# MIMXRT685S_cm33 register map
Vendor: nxp.com; File version: 1.0
CPU: CM33 r2p0, little endian, MPU, FPU, VTOR, 3 interrupt priority bits
Registers are 32-bit, read-write, reset 0x0 unless marked. A register's access mark holds for its fields unless they carry their own. Offsets are from the block's base; [hi:lo] are bit positions; {n}, {i} and the like mark numbered series; 'fields as' and 'values as' point back to an identical list.

## AHB_SECURE_CTRL — LPC_Next0 AHB secure controller
Base 0x40148000
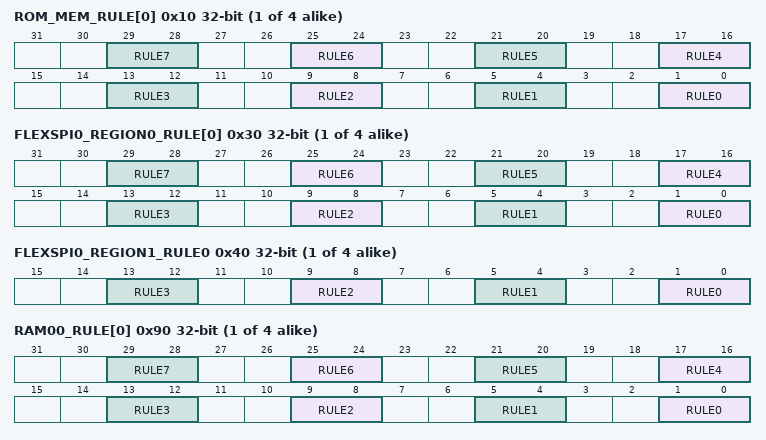
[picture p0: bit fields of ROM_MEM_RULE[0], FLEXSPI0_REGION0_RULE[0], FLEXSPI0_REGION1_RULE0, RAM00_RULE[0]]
{0x10+4i} ROM_MEM_RULE[{i}] (i=0..3) — Memory ROM Rule(n) Register
  [all] fields
    0=NONSECURE_NONPRIV_USER_ALLOWED (Non-secure and non-privilege user access allowed); 1=NONSECURE_PRIV_USER_ALLOWED (Non-secure and privilege access allowed); 2=SECURE_NONPRIV_USER_ALLOWED (Secure and non-privilege user access allowed); 3=SECURE_PRIV_USER_ALLOWED (Secure and privilege user access allowed)
  [4n+1:4n] RULE{n} (n=0..7)
{0x30+4i} FLEXSPI0_REGION0_RULE[{i}] (i=0..3) — FLEXSPI0 Region 0 Rule(n) Register
  fields as ROM_MEM_RULE[0]
{0x30+0x10*i} FLEXSPI0_REGION{i}_RULE0 (i=1..4)
  [all] fields
    values as the fields of ROM_MEM_RULE[0]
  [4n+1:4n] RULE{n} (n=0..3)
{0x90+4i} RAM00_RULE[{i}] (i=0..3) — SRAM Partition 00 Rule(n) Register
  fields as ROM_MEM_RULE[0]
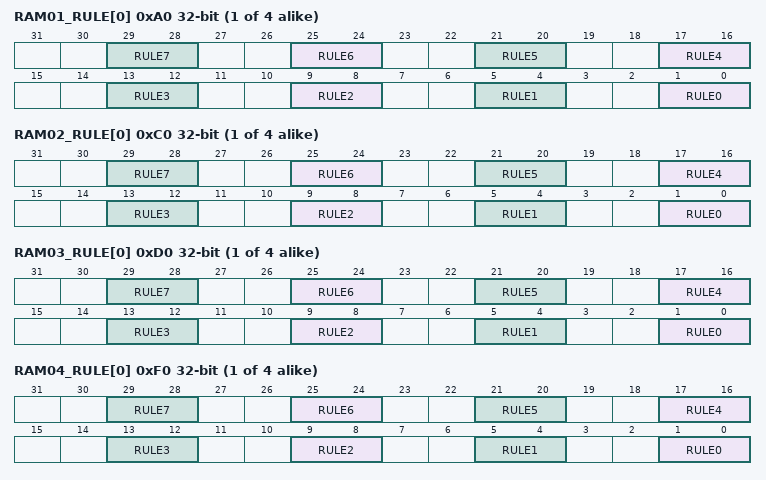
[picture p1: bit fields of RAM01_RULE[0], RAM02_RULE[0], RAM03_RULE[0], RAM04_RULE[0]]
{0xA0+4i} RAM01_RULE[{i}] (i=0..3) — SRAM Partition 01 Rule(n) Register
  fields as ROM_MEM_RULE[0]
{0xC0+4i} RAM02_RULE[{i}] (i=0..3) — SRAM Partition 02 Rule(n) Register
  fields as ROM_MEM_RULE[0]
{0xD0+4i} RAM03_RULE[{i}] (i=0..3) — SRAM Partition 03 Rule(n) Register
  fields as ROM_MEM_RULE[0]
{0xF0+4i} RAM04_RULE[{i}] (i=0..3) — SRAM Partition 04 Rule(n) Register
  fields as ROM_MEM_RULE[0]
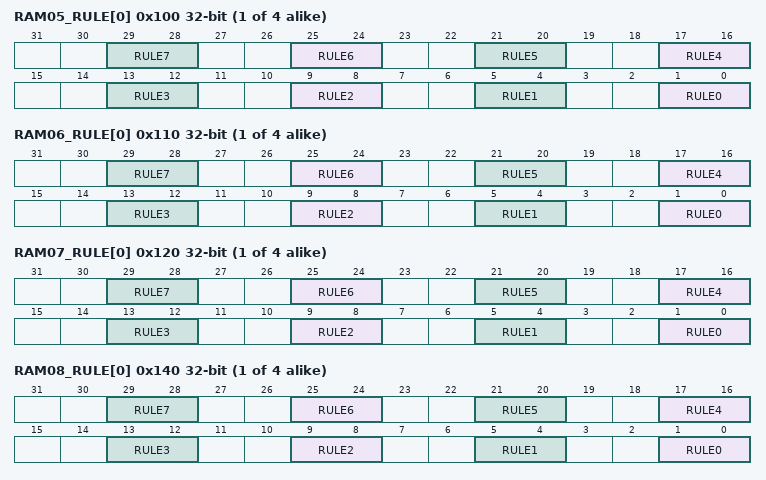
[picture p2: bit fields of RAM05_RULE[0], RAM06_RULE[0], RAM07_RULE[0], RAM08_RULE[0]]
{0x100+4i} RAM05_RULE[{i}] (i=0..3) — SRAM Partition 05 Rule(n) Register
  fields as ROM_MEM_RULE[0]
{0x110+4i} RAM06_RULE[{i}] (i=0..3) — SRAM Partition 06 Rule(n) Register
  fields as ROM_MEM_RULE[0]
{0x120+4i} RAM07_RULE[{i}] (i=0..3) — SRAM Partition 07 Rule(n) Register
  fields as ROM_MEM_RULE[0]
{0x140+4i} RAM08_RULE[{i}] (i=0..3) — SRAM Partition 08 Rule(n) Register
  fields as ROM_MEM_RULE[0]
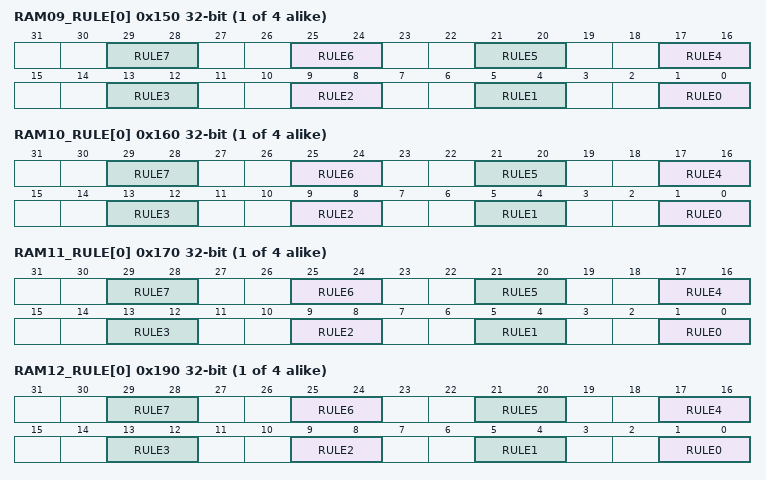
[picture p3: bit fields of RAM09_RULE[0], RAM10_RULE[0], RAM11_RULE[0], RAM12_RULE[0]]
{0x150+4i} RAM09_RULE[{i}] (i=0..3) — SRAM Partition 09 Rule(n) Register
  fields as ROM_MEM_RULE[0]
{0x160+4i} RAM10_RULE[{i}] (i=0..3) — SRAM Partition 10 Rule(n) Register
  fields as ROM_MEM_RULE[0]
{0x170+4i} RAM11_RULE[{i}] (i=0..3) — SRAM Partition 11 Rule(n) Register
  fields as ROM_MEM_RULE[0]
{0x190+4i} RAM12_RULE[{i}] (i=0..3) — SRAM Partition 12 Rule(n) Register
  fields as ROM_MEM_RULE[0]
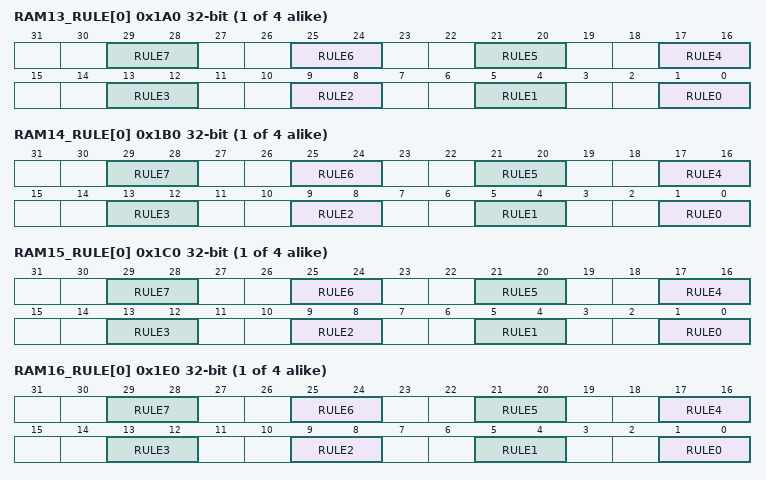
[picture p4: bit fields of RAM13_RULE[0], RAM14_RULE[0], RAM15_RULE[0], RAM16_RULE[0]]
{0x1A0+4i} RAM13_RULE[{i}] (i=0..3) — SRAM Partition 13 Rule(n) Register
  fields as ROM_MEM_RULE[0]
{0x1B0+4i} RAM14_RULE[{i}] (i=0..3) — SRAM Partition 14 Rule(n) Register
  fields as ROM_MEM_RULE[0]
{0x1C0+4i} RAM15_RULE[{i}] (i=0..3) — SRAM Partition 15 Rule(n) Register
  fields as ROM_MEM_RULE[0]
{0x1E0+4i} RAM16_RULE[{i}] (i=0..3) — SRAM Partition 16 Rule(n) Register
  fields as ROM_MEM_RULE[0]
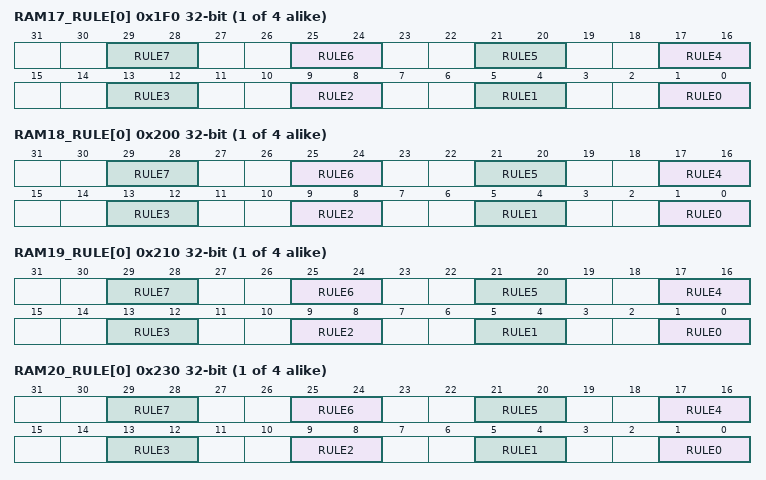
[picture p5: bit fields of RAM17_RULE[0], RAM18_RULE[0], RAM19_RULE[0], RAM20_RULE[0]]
{0x1F0+4i} RAM17_RULE[{i}] (i=0..3) — SRAM Partition 17 Rule(n) Register
  fields as ROM_MEM_RULE[0]
{0x200+4i} RAM18_RULE[{i}] (i=0..3) — SRAM Partition 18 Rule(n) Register
  fields as ROM_MEM_RULE[0]
{0x210+4i} RAM19_RULE[{i}] (i=0..3) — SRAM Partition 19 Rule(n) Register
  fields as ROM_MEM_RULE[0]
{0x230+4i} RAM20_RULE[{i}] (i=0..3) — SRAM Partition 20 Rule(n) Register
  fields as ROM_MEM_RULE[0]
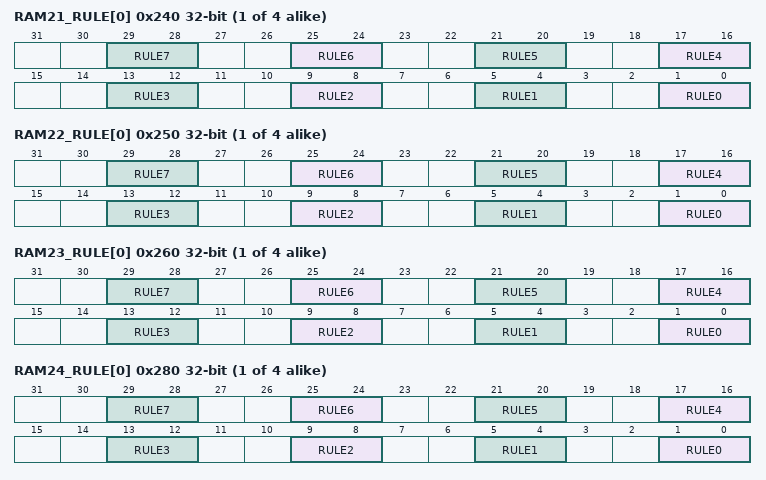
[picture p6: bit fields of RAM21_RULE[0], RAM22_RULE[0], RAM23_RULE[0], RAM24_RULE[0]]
{0x240+4i} RAM21_RULE[{i}] (i=0..3) — SRAM Partition 21 Rule(n) Register
  fields as ROM_MEM_RULE[0]
{0x250+4i} RAM22_RULE[{i}] (i=0..3) — SRAM Partition 22 Rule(n) Register
  fields as ROM_MEM_RULE[0]
{0x260+4i} RAM23_RULE[{i}] (i=0..3) — SRAM Partition 23 Rule(n) Register
  fields as ROM_MEM_RULE[0]
{0x280+4i} RAM24_RULE[{i}] (i=0..3) — SRAM Partition 24 Rule(n) Register
  fields as ROM_MEM_RULE[0]
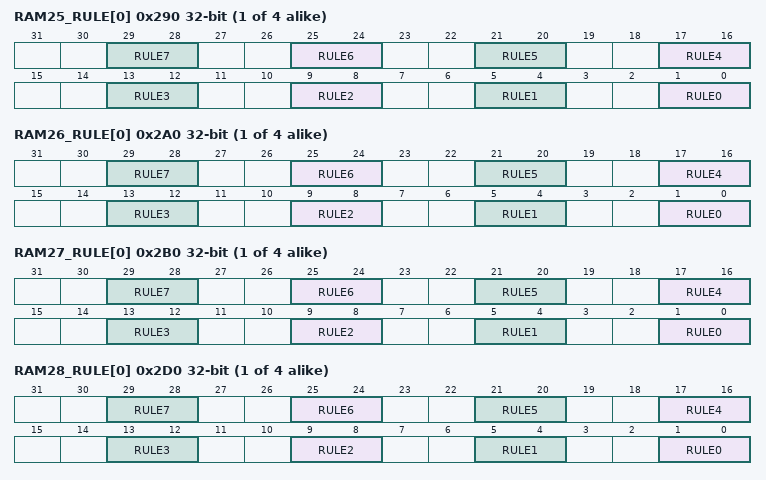
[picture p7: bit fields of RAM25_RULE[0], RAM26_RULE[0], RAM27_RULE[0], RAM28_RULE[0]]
{0x290+4i} RAM25_RULE[{i}] (i=0..3) — SRAM Partition 25 Rule(n) Register
  fields as ROM_MEM_RULE[0]
{0x2A0+4i} RAM26_RULE[{i}] (i=0..3) — SRAM Partition 26 Rule(n) Register
  fields as ROM_MEM_RULE[0]
{0x2B0+4i} RAM27_RULE[{i}] (i=0..3) — SRAM Partition 27 Rule(n) Register
  fields as ROM_MEM_RULE[0]
{0x2D0+4i} RAM28_RULE[{i}] (i=0..3) — SRAM Partition 28 Rule(n) Register
  fields as ROM_MEM_RULE[0]
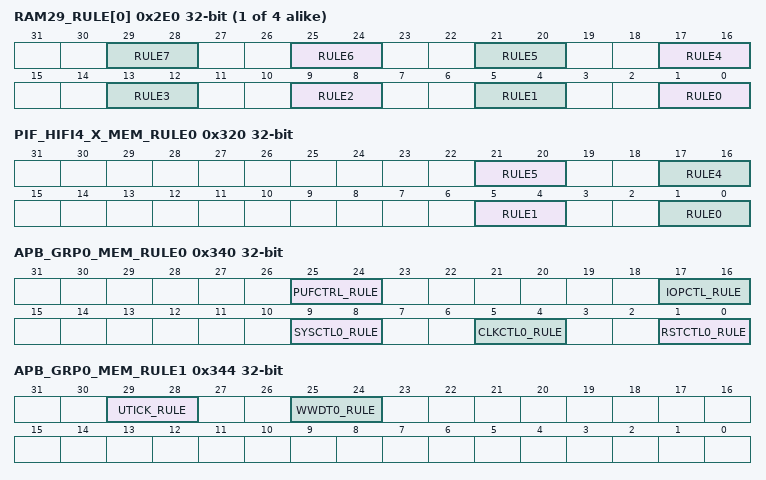
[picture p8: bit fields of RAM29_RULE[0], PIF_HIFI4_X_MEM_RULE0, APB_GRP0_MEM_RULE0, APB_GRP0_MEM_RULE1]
{0x2E0+4i} RAM29_RULE[{i}] (i=0..3) — SRAM Partition 29 Rule(n) Register
  fields as ROM_MEM_RULE[0]
0x320 PIF_HIFI4_X_MEM_RULE0 — Security access rules for HiFi 4 memory sectors (0x24000000--0x240FFFFF). Each sector is 32 Kbytes, there're 4 sectors in total.
  [21:20] RULE5 — secure control rule5. it can be set when check_reg's write_lock is '0'
  [17:16] RULE4 — secure control rule4. it can be set when check_reg's write_lock is '0'
  [5:4] RULE1 — secure control rule1. it can be set when check_reg's write_lock is '0'
  [1:0] RULE0 — secure control rule0. it can be set when check_reg's write_lock is '0'
0x340 APB_GRP0_MEM_RULE0 — Security access rules for APB Bridge 0 peripherals. Each APB bridge sector is 4 Kbytes, there're 16 sectors in total.
  [25:24] PUFCTRL_RULE — 0x4000 6000--0x4000 6FFF
  [17:16] IOPCTL_RULE — 0x4000 4000--0x4000 4FFF
  [9:8] SYSCTL0_RULE — 0x4000 2000--0x4000 2FFF
  [5:4] CLKCTL0_RULE — 0x4000 1000--0x4000 1FFF
  [1:0] RSTCTL0_RULE — 0x4000 0000--0x4000 0FFF
0x344 APB_GRP0_MEM_RULE1 — Security access rules for APB Bridge 0 peripherals. Each APB bridge sector is 4 Kbytes, there're 16 sectors in total.
  [29:28] UTICK_RULE — 0x4000 F000--0x4000 FFFF
  [25:24] WWDT0_RULE — 0x4000 E000--0x4000 EFFF
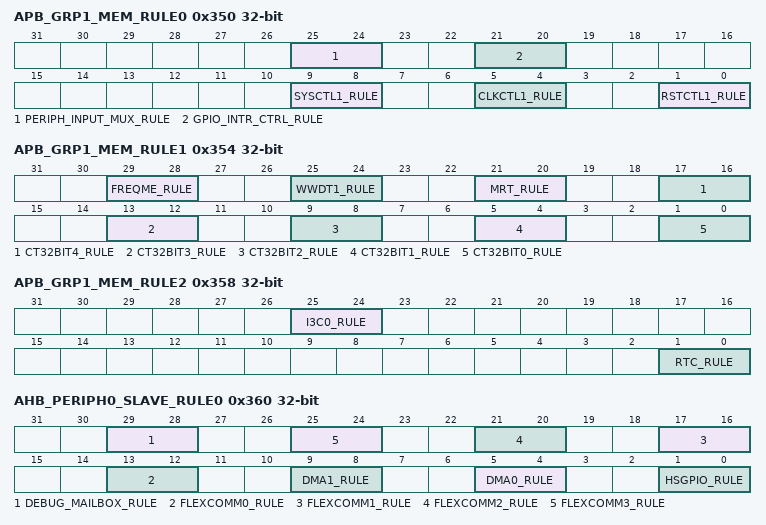
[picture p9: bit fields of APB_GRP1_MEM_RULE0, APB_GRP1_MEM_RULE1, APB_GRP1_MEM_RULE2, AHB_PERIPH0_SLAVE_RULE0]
0x350 APB_GRP1_MEM_RULE0 — Security access rules for APB Bridge 1 peripherals. Each APB bridge sector is 4 Kbytes, there're 16 sectors in total.
  [25:24] PERIPH_INPUT_MUX_RULE — 0x4002 6000--0x4002 6FFF
  [21:20] GPIO_INTR_CTRL_RULE — 0x4002 5000--0x4002 5FFF
  [9:8] SYSCTL1_RULE — 0x4002 2000--0x4002 2FFF
  [5:4] CLKCTL1_RULE — 0x4002 1000--0x4002 1FFF
  [1:0] RSTCTL1_RULE — 0x4002 0000--0x4002 0FFF
0x354 APB_GRP1_MEM_RULE1 — Security access rules for APB Bridge 1 peripherals. Each APB bridge sector is 4 Kbytes, there're 16 sectors in total.
  [29:28] FREQME_RULE — 0x4002 F000--0x4002 FFFF
  [25:24] WWDT1_RULE — 0x4002 E000--0x4002 EFFF
  [21:20] MRT_RULE — 0x4002 D000--0x4002 DFFF
  [17:16] CT32BIT4_RULE — 0x4002 C000--0x4002 CFFF
  [13:12] CT32BIT3_RULE — 0x4002 B000--0x4002 BFFF
  [9:8] CT32BIT2_RULE — 0x4002 A000--0x4002 AFFF
  [5:4] CT32BIT1_RULE — 0x4002 9000--0x4002 9FFF
  [1:0] CT32BIT0_RULE — 0x4002 8000--0x4002 8FFF
0x358 APB_GRP1_MEM_RULE2 — Security access rules for APB Bridge 1 peripherals. Each APB bridge sector is 4 Kbytes, there're 16 sectors in total.
  [25:24] I3C0_RULE — 0x4003 6000--0x4003 6FFF
  [1:0] RTC_RULE — 0x4003 0000--0x4003 0FFF
0x360 AHB_PERIPH0_SLAVE_RULE0 — Security access rules for AHB peripheral slaves area 0x40100000--0x4010FFFF
  [29:28] DEBUG_MAILBOX_RULE — 0x4010F000--0x4010FFFF
  [4n+13:4n+12] FLEXCOMM{n}_RULE (n=0..3) — {0x40106000+0x1000*n}--{0x40106FFF+0x1000*n}
  [9:8] DMA1_RULE — 0x40105000--0x40105FFF
  [5:4] DMA0_RULE — 0x40104000--0x40104FFF
  [1:0] HSGPIO_RULE — 0x40100000--0x40103FFF
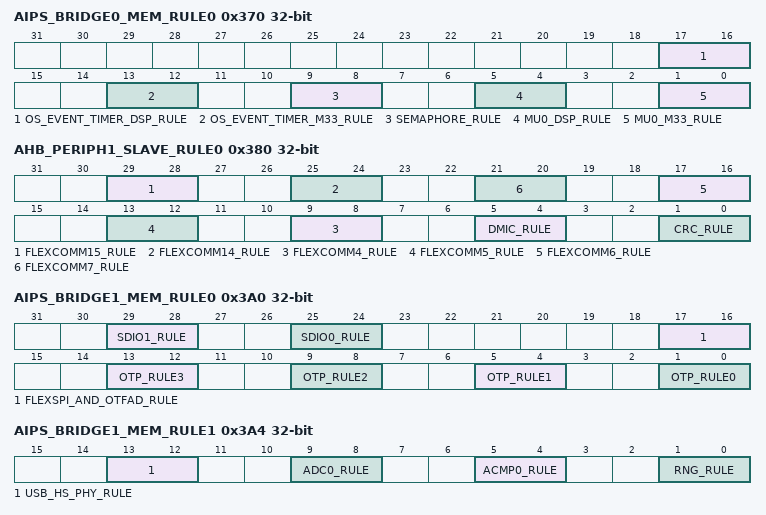
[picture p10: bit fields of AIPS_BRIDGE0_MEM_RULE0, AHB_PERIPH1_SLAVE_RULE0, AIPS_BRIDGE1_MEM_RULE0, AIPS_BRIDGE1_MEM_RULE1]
0x370 AIPS_BRIDGE0_MEM_RULE0 — 0x40110000--0x4011FFFF
  [17:16] OS_EVENT_TIMER_DSP_RULE — 0x4011 4000--0x4011 4FFF
  [13:12] OS_EVENT_TIMER_M33_RULE — 0x4011 3000--0x4011 3FFF
  [9:8] SEMAPHORE_RULE — 0x4011 2000--0x4011 2FFF
  [5:4] MU0_DSP_RULE — 0x4011 1000--0x4011 1FFF
  [1:0] MU0_M33_RULE — 0x4011 0000--0x4011 0FFF
0x380 AHB_PERIPH1_SLAVE_RULE0 — the memory map is 0x40120000--0x40127FFF
  [29:28] FLEXCOMM15_RULE — 0x40127000--0x40127FFF
  [25:24] FLEXCOMM14_RULE — 0x40126000--0x40126FFF
  [4n-7:4n-8] FLEXCOMM{n}_RULE (n=4..7) — {0x4011E000+0x1000*n}--{0x4011EFFF+0x1000*n}
  [5:4] DMIC_RULE — 0x40121000--0x40121FFF
  [1:0] CRC_RULE — Security access rules for AHB peripheral slaves area 0x40120000--0x40120FFF
0x3A0 AIPS_BRIDGE1_MEM_RULE0 — Security access rules for AIPS Bridge peripherals. Each AIPS bridge sector is 4 Kbytes, there're 16 sectors in total.
  [29:28] SDIO1_RULE — 0x4013 7000--0x4013 7FFF
  [25:24] SDIO0_RULE — 0x4013 6000--0x4013 6FFF
  [17:16] FLEXSPI_AND_OTFAD_RULE — 0x4013 4000--0x4013 4FFF
  [4n+1:4n] OTP_RULE{n} (n=0..3) — 0x4013 {1000n:04}--0x4013 {n}FFF
0x3A4 AIPS_BRIDGE1_MEM_RULE1 — Security access rules for AIPS Bridge peripherals. Each AIPS bridge sector is 4 Kbytes, there're 16 sectors in total.
  [13:12] USB_HS_PHY_RULE — 0x4013 B000--0x4013 BFFF
  [9:8] ADC0_RULE — 0x4013 A000--0x4013 AFFF
  [5:4] ACMP0_RULE — 0x4013 9000--0x4013 9FFF
  [1:0] RNG_RULE — 0x4013 8000--0x4013 8FFF
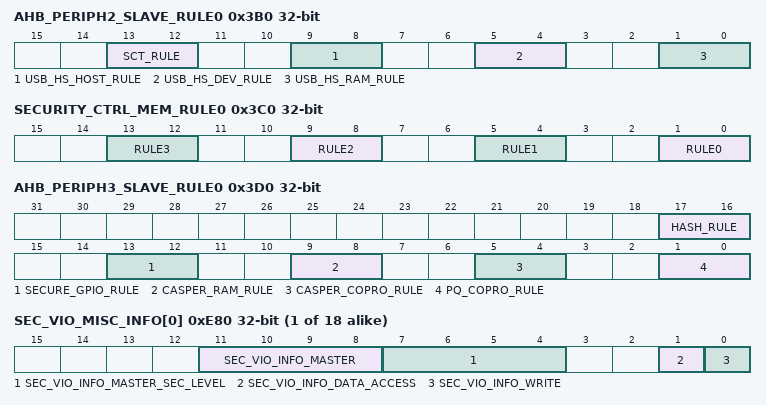
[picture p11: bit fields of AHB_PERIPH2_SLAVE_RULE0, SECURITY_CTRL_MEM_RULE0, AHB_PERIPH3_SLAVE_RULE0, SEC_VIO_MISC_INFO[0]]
0x3B0 AHB_PERIPH2_SLAVE_RULE0 — Security access rules for AHB peripheral slaves area 0x40140000--0x4014BFFF
  [13:12] SCT_RULE — 0x40146000--0x40146FFF
  [9:8] USB_HS_HOST_RULE — 0x40145000--0x40145FFF
  [5:4] USB_HS_DEV_RULE — 0x40144000--0x40144FFF
  [1:0] USB_HS_RAM_RULE — 0x40140000--0x40143FFF
0x3C0 SECURITY_CTRL_MEM_RULE0 — 0x40148000--0x4014BFFF
  [4n+1:4n] RULE{n} (n=0..3) — secure control rule0. it can be set when check_reg's write_lock is '0'
0x3D0 AHB_PERIPH3_SLAVE_RULE0 — Security access rules for AHB peripheral slaves area 0x40150000--0x40158FFF
  [17:16] HASH_RULE — 0x40158000--0x40158FFF
  [13:12] SECURE_GPIO_RULE — 0x40154000--0x40157FFF
  [9:8] CASPER_RAM_RULE — 0x40152000--0x40152FFF
  [5:4] CASPER_COPRO_RULE — 0x40151000--0x40151FFF
  [1:0] PQ_COPRO_RULE — 0x40150000--0x40150FFF
{0xE00+4i} SEC_VIO_ADDR[{i}] (i=0..17) ro — most recent security violation address for AHB layer n
  [31:0] SEC_VIO_ADDR — security violation address for AHB layer
{0xE80+4i} SEC_VIO_MISC_INFO[{i}] (i=0..17) ro — most recent security violation miscellaneous information for AHB layer n
  [11:8] SEC_VIO_INFO_MASTER — security violation master number
  [7:4] SEC_VIO_INFO_MASTER_SEC_LEVEL — bit [5:4]: master sec level and privilege level bit [7:6]: anti-pol value for master sec level and privilege level
  [1] SEC_VIO_INFO_DATA_ACCESS — security violation access data/code indicator, 0: code, 1
  [0] SEC_VIO_INFO_WRITE — security violation access read/write indicator, 0: read, 1: write
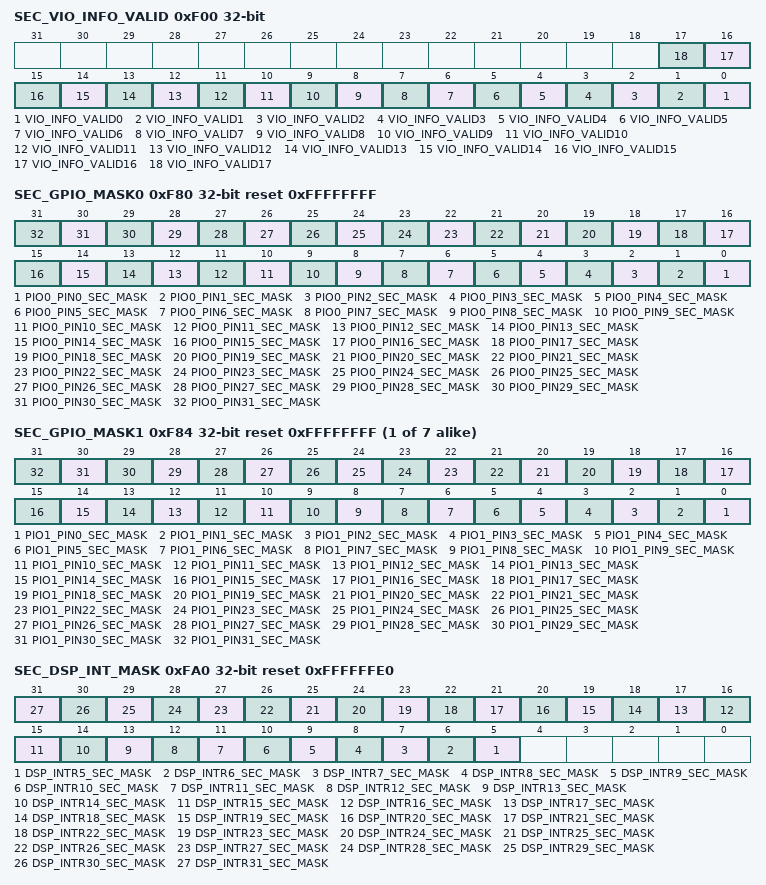
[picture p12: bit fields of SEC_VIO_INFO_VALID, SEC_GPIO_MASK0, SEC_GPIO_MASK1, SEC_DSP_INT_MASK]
0xF00 SEC_VIO_INFO_VALID — security violation address/information registers valid flags
  [n] VIO_INFO_VALID{n} (n=0..17) — violation information valid flag for AHB layer {n}. 0: not valid. 1: valid (violation occurred). Write 1 to clear.
0xF80 SEC_GPIO_MASK0 reset 0xFFFFFFFF — Secure GPIO mask for port 0 pins. This register is used to block leakage of Secure interface (GPIOs, I2C, UART configured as secure peripherals) pin states to non-secure world.
  [n] PIO0_PIN{n}_SEC_MASK (n=0..31) — 0 : Pin PIO0_{n} state is readable by non-secure world through non-secure GPIO port control registers
{0xF80+4i} SEC_GPIO_MASK{i} reset 0xFFFFFFFF (i=1..7) — Secure GPIO mask for port {i} pins.
  [n] PIO{i}_PIN{n}_SEC_MASK (n=0..31) — 0 : Pin PIO{i}_{n} state is readable by non-secure world through non-secure GPIO port control registers
0xFA0 SEC_DSP_INT_MASK reset 0xFFFFFFE0 — secure general purpose register 8 used to mask interrupts to DSP for security purpose
  [n] DSP_INTR{n}_SEC_MASK (n=5..31) — 0: INTR{n} is invisible to DSP, 1: INTR{n} is visible to DSP
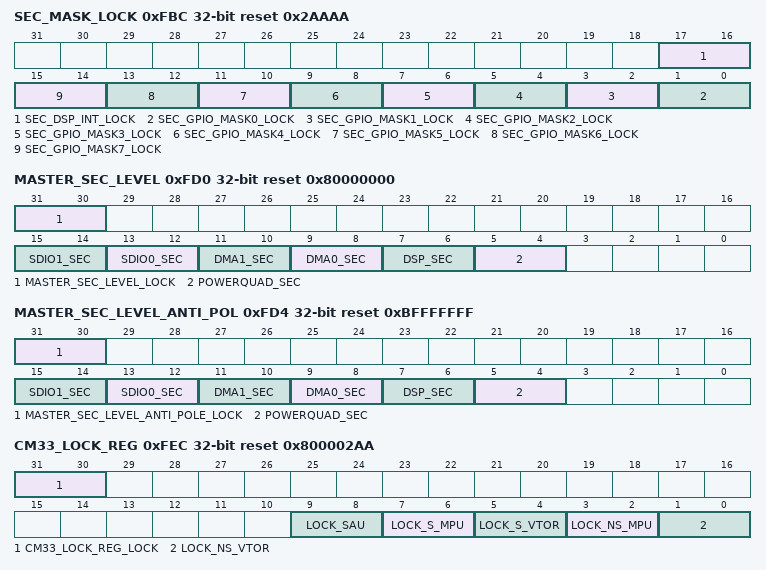
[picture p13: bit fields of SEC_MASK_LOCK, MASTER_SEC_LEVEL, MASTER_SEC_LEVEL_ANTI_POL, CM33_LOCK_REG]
0xFBC SEC_MASK_LOCK reset 0x2AAAA — sec_gp_reg write-lock bits
  [all] fields
    1=BLOCKED (Restrictive mode.); 2=WRITABLE
  [17:16] SEC_DSP_INT_LOCK — SEC_DSP_INT_MASK register write-lock.
  [2n+1:2n] SEC_GPIO_MASK{n}_LOCK (n=0..7) — SEC_GPIO_MASK{n} register write-lock.
0xFD0 MASTER_SEC_LEVEL reset 0x80000000 — master secure level register
  [31:30] MASTER_SEC_LEVEL_LOCK — MASTER_SEC_LEVEL register write-lock.
    1=BLOCKED (Restrictive mode.); 2=WRITABLE
  [15:14] SDIO1_SEC — SDIO1 master secure level control.
    0=ENUM_NS_NP (Non-secure and Non-priviledge user access allowed.); 1=ENUM_NS_P (Non-secure and Privilege access allowed.); 2=ENUM_S_NP (Secure and Non-priviledge user access allowed.); 3=ENUM_S_P (Secure and Priviledge user access allowed.)
  [13:12] SDIO0_SEC — SDIO0 master secure level control.
    values as SDIO1_SEC
  [11:10] DMA1_SEC — DMA1 master secure level control.
    values as SDIO1_SEC
  [9:8] DMA0_SEC — DMA0 master secure level control.
    values as SDIO1_SEC
  [7:6] DSP_SEC — DSP master secure level control.
    values as SDIO1_SEC
  [5:4] POWERQUAD_SEC — POWERQUAD master secure level control.
    values as SDIO1_SEC
0xFD4 MASTER_SEC_LEVEL_ANTI_POL reset 0xBFFFFFFF — master secure level anti-pole register
  [31:30] MASTER_SEC_LEVEL_ANTI_POLE_LOCK — MASTER_SEC_LEVEL_ANTI_POL register write-lock.
    1=BLOCKED (Restrictive mode.); 2=WRITABLE
  [15:14] SDIO1_SEC — SDIO1 master secure level control anti-pole value (i.e It must be written with the inverted value of the corresponding field in master_sec_reg).
    0=ENUM_S_P (Secure and Priviledge user access allowed.); 1=ENUM_S_NP (Secure and Non-priviledge user access allowed.); 2=ENUM_NS_P (Non-secure and Privilege access allowed.); 3=ENUM_NS_NP (Non-secure and Non-priviledge user access allowed.)
  [13:12] SDIO0_SEC — SDIO0 master secure level control anti-pole value (i.e It must be written with the inverted value of the corresponding field in master_sec_reg).
    values as SDIO1_SEC
  [11:10] DMA1_SEC — DMA1 master secure level control anti-pole value (i.e It must be written with the inverted value of the corresponding field in master_sec_reg).
    values as SDIO1_SEC
  [9:8] DMA0_SEC — DMA0 master secure level control anti-pole value (i.e It must be written with the inverted value of the corresponding field in master_sec_reg).
    values as SDIO1_SEC
  [7:6] DSP_SEC — DSP master secure level control anti-pole value (i.e It must be written with the inverted value of the corresponding field in master_sec_reg).
    values as SDIO1_SEC
  [5:4] POWERQUAD_SEC — POWERQUAD master secure level control anti-pole value (i.e It must be written with the inverted value of the corresponding field in master_sec_reg).
    values as SDIO1_SEC
0xFEC CM33_LOCK_REG reset 0x800002AA — m33 lock control register
  [31:30] CM33_LOCK_REG_LOCK — CM33_LOCK_REG_LOCK write-lock.
    1=BLOCKED (Restricted mode.); 2=WRITABLE
  [9:8] LOCK_SAU — m33 LOCKSAU write-lock.
    1=BLOCKED (Restricted mode.); 2=WRITABLE
  [7:6] LOCK_S_MPU — m33 LOCKSMPU write-lock.
    1=BLOCKED (Restricted mode.); 2=WRITABLE
  [5:4] LOCK_S_VTOR — m33 LOCKSVTOR write-lock.
    1=BLOCKED (Restricted mode.); 2=WRITABLE
  [3:2] LOCK_NS_MPU — m33 LOCKNSMPU write-lock.
    1=BLOCKED (Restricted mode.); 2=WRITABLE
  [1:0] LOCK_NS_VTOR — m33 LOCKNSVTOR write-lock.
    1=BLOCKED (Restrictive mode.); 2=WRITABLE
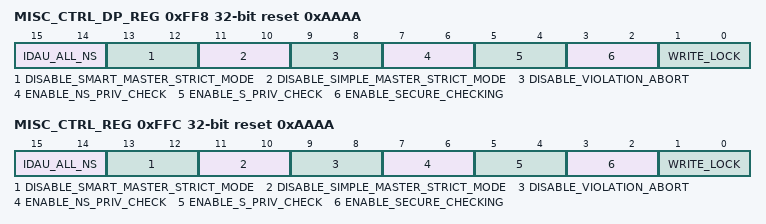
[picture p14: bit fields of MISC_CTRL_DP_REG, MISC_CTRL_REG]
0xFF8 MISC_CTRL_DP_REG reset 0xAAAA — secure control duplicate register
  [15:14] IDAU_ALL_NS — Disable IDAU.
    1=DISABLE (IDAU is disabled.); 2=ENABLE (IDAU is enabled.)
  [13:12] DISABLE_SMART_MASTER_STRICT_MODE
    1=TIER_MODE (Smart master in tier mode.); 2=STRICT_MODE (Smart master in strict mode.)
  [11:10] DISABLE_SIMPLE_MASTER_STRICT_MODE
    1=TIER_MODE (Simple master in tier mode.); 2=STRICT_MODE (Simple master in strict mode.)
  [9:8] DISABLE_VIOLATION_ABORT — Disable secure violation abort.
    1=DISABLE (Violation assert secure_violation_irq.); 2=ENABLE (Violation causes abort.)
  [7:6] ENABLE_NS_PRIV_CHECK — AHB bus matrix enable non-secure privilege check.
    1=ENABLE (Restrictive mode.); 2=DISABLE (Disable check.)
  [5:4] ENABLE_S_PRIV_CHECK — AHB bus matrix enable secure privilege check.
    1=ENABLE (Restrictive mode.); 2=DISABLE (Disable check.)
  [3:2] ENABLE_SECURE_CHECKING — AHB bus matrix enable secure checking.
    1=ENABLE (Restrictive mode.); 2=DISABLE (Disable check.)
  [1:0] WRITE_LOCK
    1=RESTRICTED (Restrictive mode.); 2=ACCESSIBLE (Secure control registers can be written.)
0xFFC MISC_CTRL_REG reset 0xAAAA — secure control register
  fields as MISC_CTRL_DP_REG
